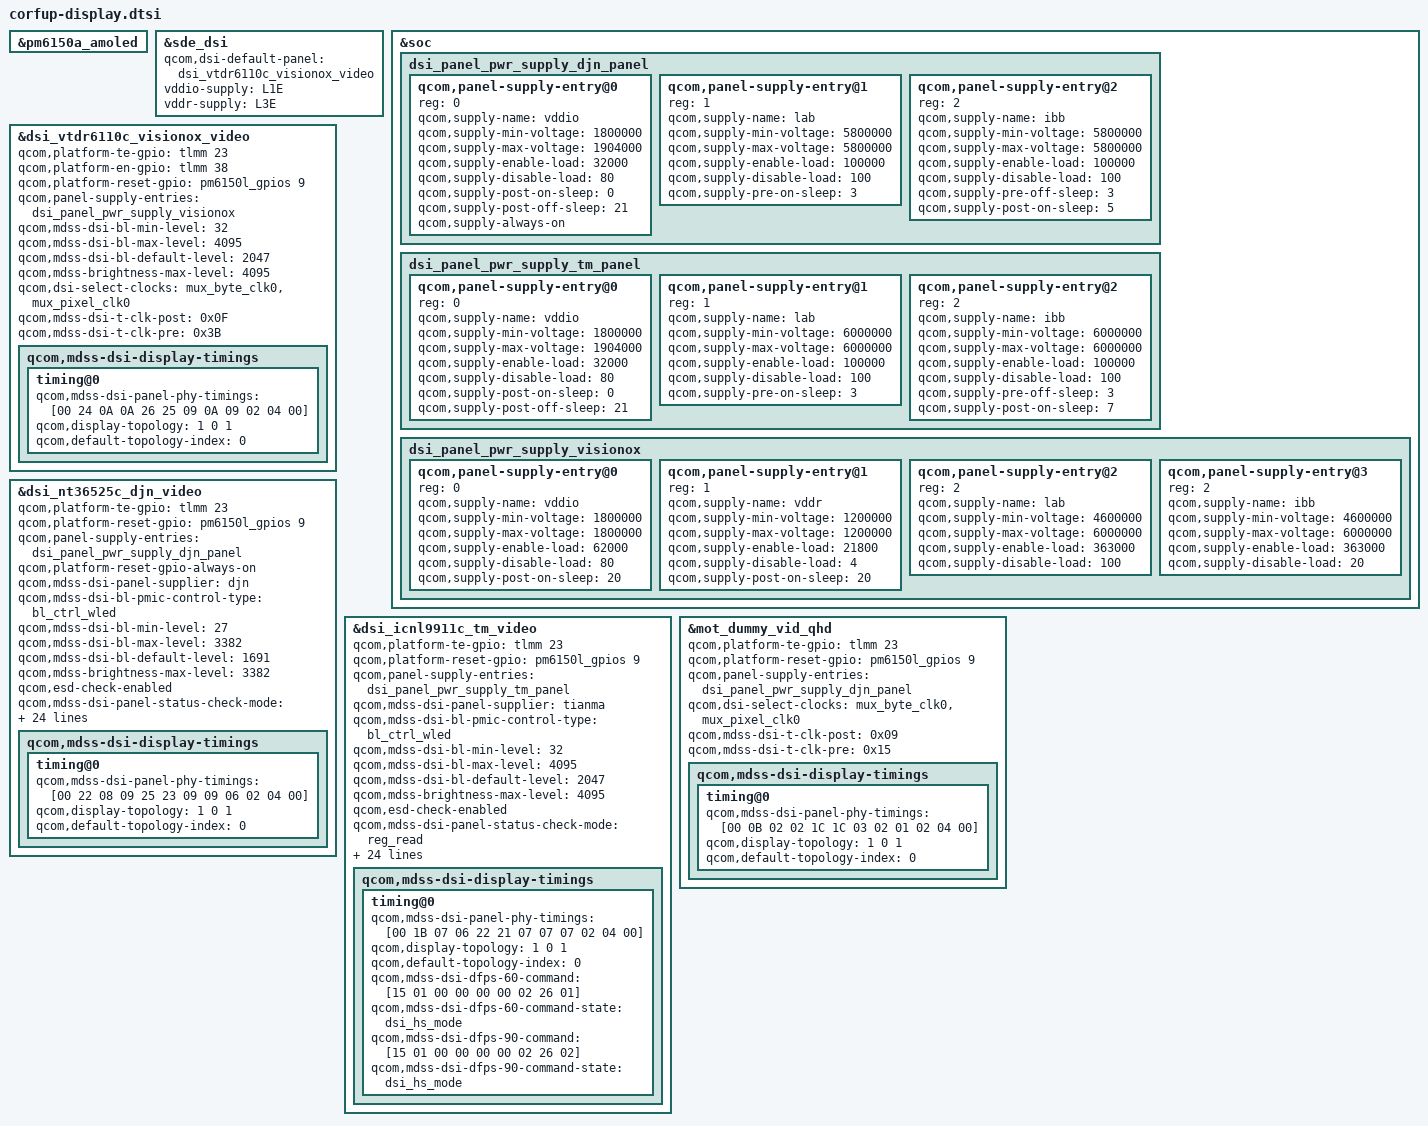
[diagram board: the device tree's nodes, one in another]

#include "dsi-panel-mot-djn-nt36525c-hd-video.dtsi"
#include "dsi-panel-mot-tm-icnl9911c-hd-video.dtsi"
#include "dsi-panel-mot-visionox-vtdr6110c-fhd-video.dtsi"
#include "dsi-panel-mot-dummy-qhd-video.dtsi"



&pm6150a_amoled {
	status = "ok";
};

&sde_dsi {
	/delete-property/ qcom,dsi-default-panel;
	qcom,dsi-default-panel = <&dsi_vtdr6110c_visionox_video>;

	vddio-supply = <&L1E>;
	vddr-supply = <&L3E>;
};

&soc {
	dsi_panel_pwr_supply_djn_panel: dsi_panel_pwr_supply_djn_panel{
		#address-cells = <1>;
		#size-cells = <0>;
		qcom,panel-supply-entry@0 {
			reg = <0>;
			qcom,supply-name = "vddio";
			qcom,supply-min-voltage = <1800000>;
			qcom,supply-max-voltage = <1904000>;
			qcom,supply-enable-load = <32000>;
			qcom,supply-disable-load = <80>;
			qcom,supply-post-on-sleep= <0>;
			qcom,supply-post-off-sleep = <21>;
			qcom,supply-always-on;
		};

		qcom,panel-supply-entry@1 {
			reg = <1>;
			qcom,supply-name = "lab";
			qcom,supply-min-voltage = <5800000>;
			qcom,supply-max-voltage = <5800000>;
			qcom,supply-enable-load = <100000>;
			qcom,supply-disable-load = <100>;
			qcom,supply-pre-on-sleep = <3>;
		};

		qcom,panel-supply-entry@2 {
			reg = <2>;
			qcom,supply-name = "ibb";
			qcom,supply-min-voltage = <5800000>;
			qcom,supply-max-voltage = <5800000>;
			qcom,supply-enable-load = <100000>;
			qcom,supply-disable-load = <100>;
			qcom,supply-pre-off-sleep = <3>;
			qcom,supply-post-on-sleep = <5>;
		};
	};

	dsi_panel_pwr_supply_tm_panel: dsi_panel_pwr_supply_tm_panel{
		#address-cells = <1>;
		#size-cells = <0>;
		qcom,panel-supply-entry@0 {
			reg = <0>;
			qcom,supply-name = "vddio";
			qcom,supply-min-voltage = <1800000>;
			qcom,supply-max-voltage = <1904000>;
			qcom,supply-enable-load = <32000>;
			qcom,supply-disable-load = <80>;
			qcom,supply-post-on-sleep= <0>;
			qcom,supply-post-off-sleep = <21>;
		};

		qcom,panel-supply-entry@1 {
			reg = <1>;
			qcom,supply-name = "lab";
			qcom,supply-min-voltage = <6000000>;
			qcom,supply-max-voltage = <6000000>;
			qcom,supply-enable-load = <100000>;
			qcom,supply-disable-load = <100>;
			qcom,supply-pre-on-sleep = <3>;
		};

		qcom,panel-supply-entry@2 {
			reg = <2>;
			qcom,supply-name = "ibb";
			qcom,supply-min-voltage = <6000000>;
			qcom,supply-max-voltage = <6000000>;
			qcom,supply-enable-load = <100000>;
			qcom,supply-disable-load = <100>;
			qcom,supply-pre-off-sleep = <3>;
			qcom,supply-post-on-sleep = <7>;
		};
	};

dsi_panel_pwr_supply_visionox: dsi_panel_pwr_supply_visionox {
	#address-cells = <1>;
	#size-cells = <0>;

	qcom,panel-supply-entry@0 {
		reg = <0>;
		qcom,supply-name = "vddio";
		qcom,supply-min-voltage = <1800000>;
		qcom,supply-max-voltage = <1800000>;
		qcom,supply-enable-load = <62000>;
		qcom,supply-disable-load = <80>;
		qcom,supply-post-on-sleep = <20>;
	};

	qcom,panel-supply-entry@1 {
		reg = <1>;
		qcom,supply-name = "vddr";
		qcom,supply-min-voltage = <1200000>;
		qcom,supply-max-voltage = <1200000>;
		qcom,supply-enable-load = <21800>;
		qcom,supply-disable-load = <4>;
		qcom,supply-post-on-sleep = <20>;
	};

	qcom,panel-supply-entry@2 {
		reg = <2>;
		qcom,supply-name = "lab";
		qcom,supply-min-voltage = <4600000>;
		qcom,supply-max-voltage = <6000000>;
		qcom,supply-enable-load = <363000>;
		qcom,supply-disable-load = <100>;
	};

	qcom,panel-supply-entry@3 {
		reg = <2>;
		qcom,supply-name = "ibb";
		qcom,supply-min-voltage = <4600000>;
		qcom,supply-max-voltage = <6000000>;
		qcom,supply-enable-load = <363000>;
		qcom,supply-disable-load = <20>;
	};
};
};

&dsi_vtdr6110c_visionox_video {
	qcom,platform-te-gpio = <&tlmm 23 0>;
	qcom,platform-en-gpio = <&tlmm 38 0>;
	qcom,platform-reset-gpio = <&pm6150l_gpios 9 0>;

	qcom,panel-supply-entries = <&dsi_panel_pwr_supply_visionox>;

	qcom,mdss-dsi-bl-min-level = <32>;
	qcom,mdss-dsi-bl-max-level = <4095>;
	qcom,mdss-dsi-bl-default-level = <2047>;
	qcom,mdss-brightness-max-level = <4095>;

	qcom,dsi-select-clocks = "mux_byte_clk0", "mux_pixel_clk0";
	qcom,mdss-dsi-t-clk-post = <0x0F>;
	qcom,mdss-dsi-t-clk-pre = <0x3B>;
	qcom,mdss-dsi-display-timings {
		timing@0 {
			qcom,mdss-dsi-panel-phy-timings = [00 24 0A 0A 26 25 09
				0A 09 02 04 00];
			qcom,display-topology = <1 0 1>;
			qcom,default-topology-index = <0>;
		};
	};
};

&dsi_nt36525c_djn_video {
	qcom,platform-te-gpio = <&tlmm 23 0>;
	qcom,platform-reset-gpio = <&pm6150l_gpios 9 0>;

	qcom,panel-supply-entries = <&dsi_panel_pwr_supply_djn_panel>;

	qcom,platform-reset-gpio-always-on;
	qcom,mdss-dsi-panel-supplier = "djn";

	qcom,mdss-dsi-bl-pmic-control-type = "bl_ctrl_wled";
	qcom,mdss-dsi-bl-min-level = <27>;
	qcom,mdss-dsi-bl-max-level = <3382>;
	qcom,mdss-dsi-bl-default-level = <1691>;
	qcom,mdss-brightness-max-level = <3382>;

	qcom,esd-check-enabled;
	qcom,mdss-dsi-panel-status-check-mode = "reg_read";
	qcom,mdss-dsi-panel-status-command = [06 01 00 01 00 00 01 0a];
	qcom,mdss-dsi-panel-status-command-state = "dsi_hs_mode";
	qcom,mdss-dsi-panel-status-value = <0x9c>;
	qcom,mdss-dsi-panel-status-read-length = <1>;

	qcom,mdss-dsi-pan-enable-dynamic-fps;
	qcom,mdss-dsi-pan-fps-update = "dfps_immediate_porch_mode_vfp";
	qcom,dsi-supported-dfps-list = <90 60>;

	qcom,mdss-dsi-hbm-on-command = [39 01 00 00 00 00 03 51 07 FF];
	qcom,mdss-dsi-hbm-on-command-state = "dsi_lp_mode";
	qcom,mdss-dsi-hbm-off-command = [39 01 00 00 00 00 03 51 06 66];
	qcom,mdss-dsi-hbm-off-command-state = "dsi_lp_mode";
	qcom,mdss-dsi-hbm-type = "lcd-dcs-wled";

	qcom,dsi-select-clocks = "mux_byte_clk0", "mux_pixel_clk0";
	qcom,mdss-dsi-t-clk-post = <0x0E>;
	qcom,mdss-dsi-t-clk-pre = <0x34>;
	qcom,mdss-dsi-display-timings {
		timing@0 {
			qcom,mdss-dsi-panel-phy-timings = [00 22 08 09 25 23 09
				09 06 02 04 00];
			qcom,display-topology = <1 0 1>;
			qcom,default-topology-index = <0>;
		};
	};
};

&dsi_icnl9911c_tm_video {
	qcom,platform-te-gpio = <&tlmm 23 0>;
	qcom,platform-reset-gpio = <&pm6150l_gpios 9 0>;

	qcom,panel-supply-entries = <&dsi_panel_pwr_supply_tm_panel>;

	qcom,mdss-dsi-panel-supplier = "tianma";

	qcom,mdss-dsi-bl-pmic-control-type = "bl_ctrl_wled";
	qcom,mdss-dsi-bl-min-level = <32>;
	qcom,mdss-dsi-bl-max-level = <4095>;
	qcom,mdss-dsi-bl-default-level = <2047>;
	qcom,mdss-brightness-max-level = <4095>;

	qcom,esd-check-enabled;
	qcom,mdss-dsi-panel-status-check-mode = "reg_read";
	qcom,mdss-dsi-panel-status-command = [06 01 00 01 00 00 01 0a];
	qcom,mdss-dsi-panel-status-command-state = "dsi_hs_mode";
	qcom,mdss-dsi-panel-status-value = <0x9c>;
	qcom,mdss-dsi-panel-status-read-length = <1>;

	qcom,mdss-dsi-pan-enable-dynamic-fps;
	qcom,mdss-dsi-pan-fps-update = "dfps_immediate_porch_mode_vfp";
	qcom,dsi-supported-dfps-list = <90 60>;
	qcom,mdss-dsi-pan-dpfs-send-command;

	qcom,mdss-dsi-hbm-on-command = [39 01 00 00 00 00 03 51 FF 0E];
	qcom,mdss-dsi-hbm-on-command-state = "dsi_lp_mode";
	qcom,mdss-dsi-hbm-off-command = [39 01 00 00 00 00 03 51 CC 0C];
	qcom,mdss-dsi-hbm-off-command-state = "dsi_lp_mode";
	qcom,mdss-dsi-hbm-type = "lcd-dcs-wled";

	qcom,dsi-select-clocks = "mux_byte_clk0", "mux_pixel_clk0";
	qcom,mdss-dsi-t-clk-post = <0x0D>;
	qcom,mdss-dsi-t-clk-pre = <0x30>;
	qcom,mdss-dsi-display-timings {
		timing@0 {
			qcom,mdss-dsi-panel-phy-timings = [00 1B 07 06 22 21 07
				07 07 02 04 00];
			qcom,display-topology = <1 0 1>;
			qcom,default-topology-index = <0>;

			qcom,mdss-dsi-dfps-60-command = [15 01 00 00 00 00 02 26 01];
			qcom,mdss-dsi-dfps-60-command-state = "dsi_hs_mode";
			qcom,mdss-dsi-dfps-90-command = [15 01 00 00 00 00 02 26 02];
			qcom,mdss-dsi-dfps-90-command-state = "dsi_hs_mode";
		};
	};
};

&mot_dummy_vid_qhd {
	qcom,platform-te-gpio = <&tlmm 23 0>;
	qcom,platform-reset-gpio = <&pm6150l_gpios 9 0>;

	qcom,panel-supply-entries = <&dsi_panel_pwr_supply_djn_panel>;

	qcom,dsi-select-clocks = "mux_byte_clk0", "mux_pixel_clk0";
	qcom,mdss-dsi-t-clk-post = <0x09>;
	qcom,mdss-dsi-t-clk-pre = <0x15>;
	qcom,mdss-dsi-display-timings {
		timing@0 {
			qcom,mdss-dsi-panel-phy-timings = [00 0B 02 02 1C 1C 03
							02 01 02 04 00];
			qcom,display-topology = <1 0 1>;
			qcom,default-topology-index = <0>;
		};
	};
};
